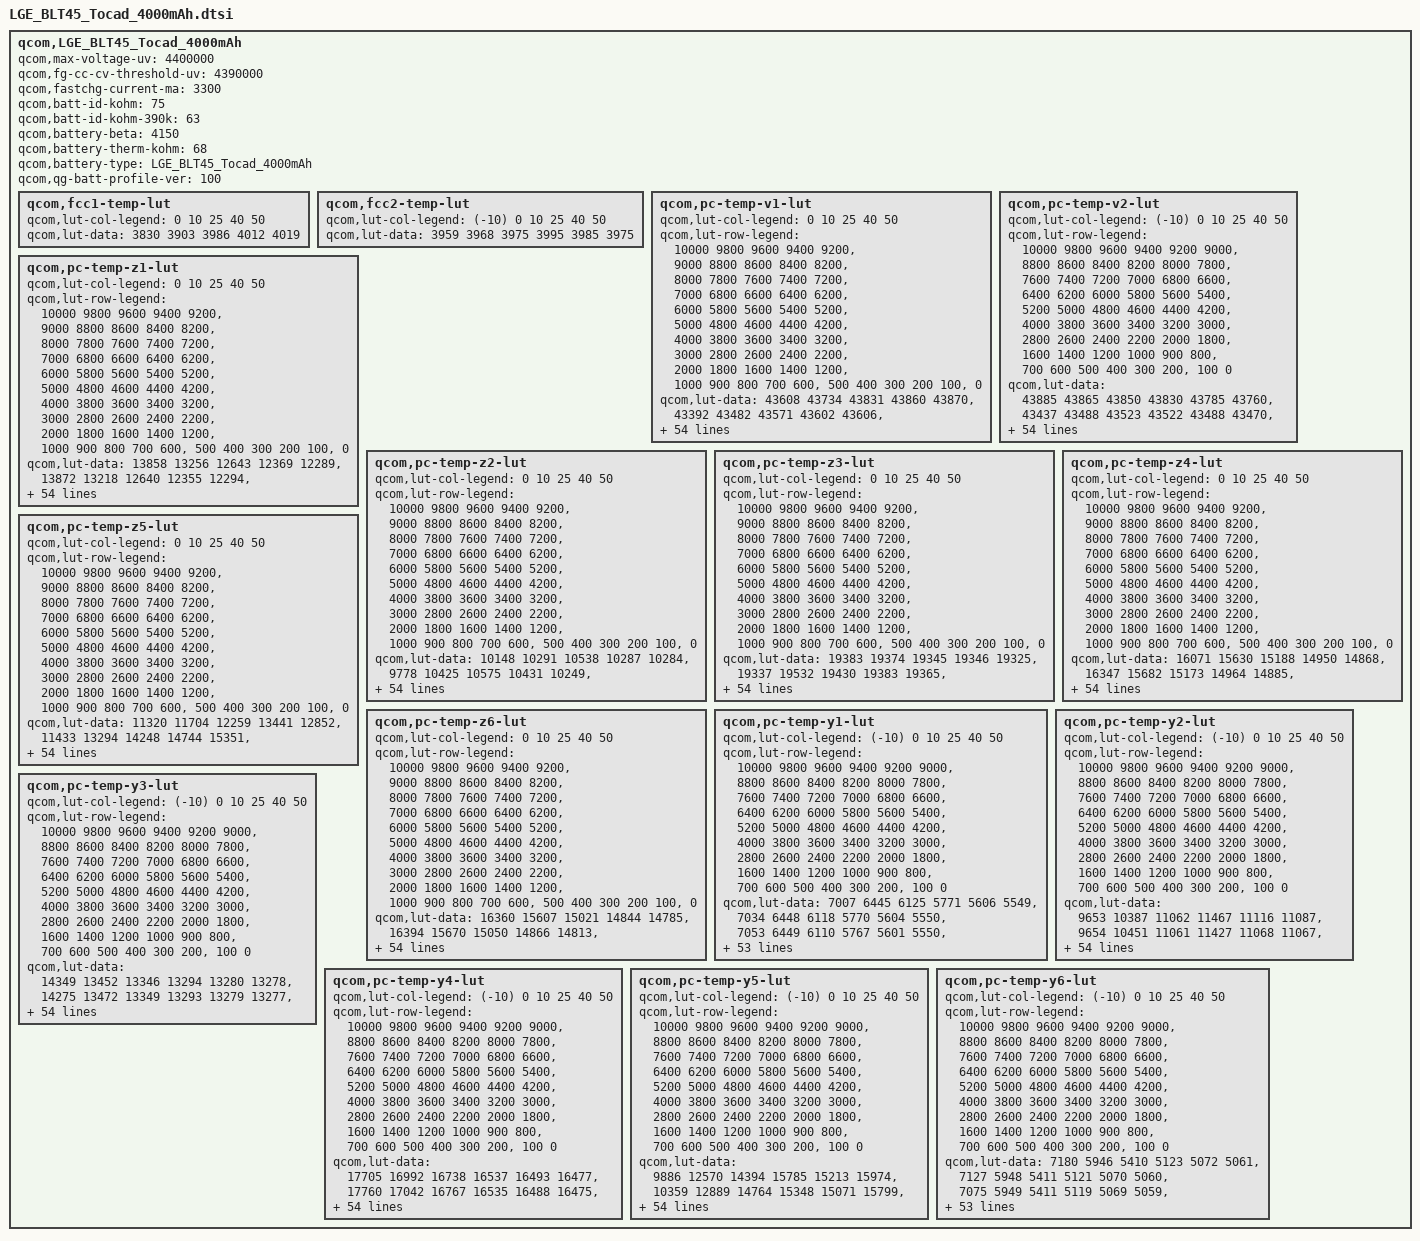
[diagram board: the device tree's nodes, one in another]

qcom,LGE_BLT45_Tocad_4000mAh {
    /* 3939240_LGE_BLT45_4000mAh_averaged_MasterSlave_Apr9th2019 */
    qcom,max-voltage-uv = <4400000>;
    qcom,fg-cc-cv-threshold-uv = <4390000>;
    qcom,fastchg-current-ma = <3300>;
    qcom,batt-id-kohm = <75>;
	qcom,batt-id-kohm-390k = <63>;
    qcom,battery-beta = <4150>;
    qcom,battery-therm-kohm = <68>;
    qcom,battery-type = "LGE_BLT45_Tocad_4000mAh";
    qcom,qg-batt-profile-ver = <100>;

	qcom,fcc1-temp-lut {
		qcom,lut-col-legend = <0 10 25 40 50>;
		qcom,lut-data = <3830 3903 3986 4012 4019>;
	};

	qcom,fcc2-temp-lut {
		qcom,lut-col-legend = <(-10) 0 10 25 40 50>;
		qcom,lut-data = <3959 3968 3975 3995 3985 3975>;
	};

	qcom,pc-temp-v1-lut {
		qcom,lut-col-legend = <0 10 25 40 50>;
		qcom,lut-row-legend = <10000 9800 9600 9400 9200>,
			<9000 8800 8600 8400 8200>,
			<8000 7800 7600 7400 7200>,
			<7000 6800 6600 6400 6200>,
			<6000 5800 5600 5400 5200>,
			<5000 4800 4600 4400 4200>,
			<4000 3800 3600 3400 3200>,
			<3000 2800 2600 2400 2200>,
			<2000 1800 1600 1400 1200>,
			<1000 900 800 700 600>,
			<500 400 300 200 100>,
			<0>;
		qcom,lut-data = <43608 43734 43831 43860 43870>,
			<43392 43482 43571 43602 43606>,
			<43120 43233 43317 43353 43362>,
			<42850 42988 43072 43110 43123>,
			<42611 42748 42835 42874 42890>,
			<42383 42512 42599 42641 42660>,
			<42159 42281 42365 42409 42430>,
			<41940 42055 42132 42179 42201>,
			<41727 41835 41904 41951 41974>,
			<41523 41619 41679 41722 41748>,
			<41325 41408 41458 41498 41524>,
			<41131 41202 41243 41280 41305>,
			<40940 41006 41031 41066 41089>,
			<40749 40821 40827 40859 40880>,
			<40538 40634 40626 40657 40675>,
			<40303 40425 40434 40462 40478>,
			<40095 40208 40249 40276 40292>,
			<39942 40028 40072 40099 40114>,
			<39813 39890 39909 39930 39942>,
			<39684 39756 39761 39774 39783>,
			<39556 39597 39594 39608 39617>,
			<39425 39421 39371 39395 39413>,
			<39283 39234 39137 39162 39188>,
			<39129 39011 38959 38981 39004>,
			<38979 38806 38811 38841 38855>,
			<38829 38694 38692 38719 38726>,
			<38690 38623 38601 38607 38610>,
			<38593 38562 38524 38505 38506>,
			<38520 38505 38446 38413 38412>,
			<38464 38454 38370 38327 38323>,
			<38425 38404 38301 38252 38244>,
			<38395 38356 38239 38184 38172>,
			<38365 38310 38184 38124 38105>,
			<38336 38270 38135 38070 38045>,
			<38307 38232 38093 38025 37992>,
			<38275 38194 38052 37979 37937>,
			<38242 38159 38012 37928 37876>,
			<38199 38117 37970 37870 37810>,
			<38131 38048 37907 37799 37732>,
			<38041 37948 37816 37709 37640>,
			<37947 37840 37713 37607 37537>,
			<37844 37722 37603 37497 37426>,
			<37713 37587 37477 37371 37301>,
			<37536 37421 37316 37214 37143>,
			<37367 37264 37167 37074 37006>,
			<37256 37167 37067 36980 36922>,
			<37215 37133 37044 36956 36894>,
			<37181 37108 37020 36936 36874>,
			<37147 37089 36999 36909 36847>,
			<37060 36999 36910 36804 36723>,
			<36773 36705 36605 36482 36388>,
			<36322 36256 36159 36035 35941>,
			<35747 35679 35583 35457 35362>,
			<34967 34895 34799 34671 34575>,
			<33730 33660 33573 33443 33346>,
			<30000 30000 30000 30000 30000>;
	};

	qcom,pc-temp-v2-lut {
		qcom,lut-col-legend = <(-10) 0 10 25 40 50>;
		qcom,lut-row-legend = <10000 9800 9600 9400 9200 9000>,
			<8800 8600 8400 8200 8000 7800>,
			<7600 7400 7200 7000 6800 6600>,
			<6400 6200 6000 5800 5600 5400>,
			<5200 5000 4800 4600 4400 4200>,
			<4000 3800 3600 3400 3200 3000>,
			<2800 2600 2400 2200 2000 1800>,
			<1600 1400 1200 1000 900 800>,
			<700 600 500 400 300 200>,
			<100 0>;
		qcom,lut-data = <43885 43865 43850 43830 43785 43760>,
			<43437 43488 43523 43522 43488 43470>,
			<43030 43147 43220 43235 43209 43197>,
			<42672 42851 42946 42972 42950 42941>,
			<42354 42594 42699 42731 42711 42702>,
			<42060 42347 42460 42497 42477 42469>,
			<41761 42096 42220 42262 42243 42236>,
			<41489 41849 41985 42030 42012 42006>,
			<41327 41595 41756 41803 41784 41779>,
			<41243 41322 41533 41579 41560 41555>,
			<41141 41095 41316 41358 41339 41335>,
			<40902 40961 41106 41142 41124 41119>,
			<40546 40853 40900 40928 40913 40907>,
			<40228 40676 40695 40722 40708 40703>,
			<39933 40358 40486 40521 40507 40505>,
			<39666 40045 40283 40326 40314 40314>,
			<39443 39841 40093 40138 40130 40129>,
			<39246 39670 39909 39957 39954 39951>,
			<39056 39478 39713 39779 39781 39777>,
			<38864 39257 39503 39608 39615 39613>,
			<38693 39042 39294 39427 39440 39440>,
			<38559 38852 39093 39209 39223 39225>,
			<38445 38679 38899 38982 38992 38994>,
			<38355 38521 38735 38804 38811 38812>,
			<38283 38369 38595 38660 38668 38670>,
			<38223 38245 38472 38535 38543 38548>,
			<38165 38164 38362 38424 38432 38436>,
			<38113 38102 38263 38325 38332 38335>,
			<38062 38048 38170 38235 38242 38243>,
			<38014 38003 38079 38154 38159 38157>,
			<37968 37962 37999 38079 38083 38079>,
			<37920 37919 37930 38008 38014 38010>,
			<37870 37877 37872 37941 37950 37946>,
			<37817 37833 37824 37876 37883 37877>,
			<37761 37786 37790 37814 37813 37800>,
			<37701 37737 37754 37748 37736 37713>,
			<37639 37682 37708 37675 37639 37606>,
			<37577 37622 37651 37598 37529 37483>,
			<37508 37554 37587 37522 37435 37379>,
			<37430 37474 37516 37450 37360 37298>,
			<37345 37384 37433 37372 37282 37220>,
			<37252 37283 37331 37276 37189 37126>,
			<37151 37168 37206 37166 37083 37020>,
			<37056 37042 37056 37033 36952 36890>,
			<36967 36909 36912 36915 36847 36786>,
			<36885 36788 36828 36857 36797 36743>,
			<36842 36743 36803 36839 36782 36728>,
			<36793 36692 36769 36815 36758 36707>,
			<36723 36631 36718 36768 36715 36659>,
			<36598 36520 36603 36646 36567 36499>,
			<36344 36281 36321 36303 36216 36126>,
			<35928 35845 35835 35806 35721 35626>,
			<35327 35242 35204 35163 35079 34980>,
			<34477 34399 34327 34291 34191 34104>,
			<33047 33059 33089 32944 32855 32565>,
			<29463 27828 27740 27731 27651 27624>;
	};

	qcom,pc-temp-z1-lut {
		qcom,lut-col-legend = <0 10 25 40 50>;
		qcom,lut-row-legend = <10000 9800 9600 9400 9200>,
			<9000 8800 8600 8400 8200>,
			<8000 7800 7600 7400 7200>,
			<7000 6800 6600 6400 6200>,
			<6000 5800 5600 5400 5200>,
			<5000 4800 4600 4400 4200>,
			<4000 3800 3600 3400 3200>,
			<3000 2800 2600 2400 2200>,
			<2000 1800 1600 1400 1200>,
			<1000 900 800 700 600>,
			<500 400 300 200 100>,
			<0>;
		qcom,lut-data = <13858 13256 12643 12369 12289>,
			<13872 13218 12640 12355 12294>,
			<13874 13206 12633 12351 12288>,
			<13873 13201 12622 12346 12283>,
			<13859 13200 12605 12340 12280>,
			<13839 13197 12591 12333 12276>,
			<13833 13194 12582 12328 12275>,
			<13836 13190 12575 12324 12274>,
			<13839 13174 12569 12322 12273>,
			<13838 13161 12563 12322 12272>,
			<13837 13155 12560 12321 12272>,
			<13834 13147 12560 12320 12272>,
			<13821 13140 12560 12319 12272>,
			<13802 13133 12559 12319 12273>,
			<13790 13128 12555 12319 12274>,
			<13779 13128 12553 12320 12275>,
			<13774 13128 12554 12321 12276>,
			<13779 13130 12556 12323 12278>,
			<13790 13136 12559 12325 12280>,
			<13796 13143 12563 12327 12282>,
			<13803 13144 12567 12330 12284>,
			<13809 13141 12571 12333 12286>,
			<13807 13140 12576 12335 12288>,
			<13801 13145 12580 12338 12291>,
			<13798 13152 12585 12342 12295>,
			<13804 13156 12589 12346 12299>,
			<13813 13159 12593 12351 12303>,
			<13815 13162 12598 12356 12306>,
			<13810 13163 12602 12361 12311>,
			<13807 13165 12607 12366 12315>,
			<13809 13167 12613 12370 12319>,
			<13815 13171 12620 12375 12323>,
			<13817 13174 12628 12380 12326>,
			<13817 13172 12632 12385 12330>,
			<13817 13166 12635 12390 12334>,
			<13817 13167 12638 12395 12337>,
			<13814 13179 12641 12399 12341>,
			<13815 13191 12646 12403 12346>,
			<13831 13197 12650 12407 12350>,
			<13854 13204 12657 12411 12354>,
			<13857 13206 12664 12416 12358>,
			<13845 13197 12672 12421 12363>,
			<13839 13194 12680 12425 12368>,
			<13832 13216 12688 12433 12372>,
			<13842 13204 12693 12441 12377>,
			<13811 13200 12697 12444 12379>,
			<13802 13197 12695 12446 12380>,
			<13805 13213 12699 12447 12382>,
			<13821 13196 12702 12450 12386>,
			<13823 13206 12711 12457 12392>,
			<13828 13226 12720 12467 12401>,
			<13828 13253 12733 12478 12411>,
			<13869 13260 12756 12495 12427>,
			<13907 13284 12779 12517 12448>,
			<13907 13284 12779 12517 12448>,
			<13907 13284 12779 12517 12448>;
	};

	qcom,pc-temp-z2-lut {
		qcom,lut-col-legend = <0 10 25 40 50>;
		qcom,lut-row-legend = <10000 9800 9600 9400 9200>,
			<9000 8800 8600 8400 8200>,
			<8000 7800 7600 7400 7200>,
			<7000 6800 6600 6400 6200>,
			<6000 5800 5600 5400 5200>,
			<5000 4800 4600 4400 4200>,
			<4000 3800 3600 3400 3200>,
			<3000 2800 2600 2400 2200>,
			<2000 1800 1600 1400 1200>,
			<1000 900 800 700 600>,
			<500 400 300 200 100>,
			<0>;
		qcom,lut-data = <10148 10291 10538 10287 10284>,
			<9778 10425 10575 10431 10249>,
			<10069 10437 10590 10479 10301>,
			<10258 10427 10580 10487 10327>,
			<10247 10413 10537 10477 10358>,
			<10223 10386 10498 10461 10383>,
			<10203 10352 10467 10437 10343>,
			<10188 10328 10445 10407 10258>,
			<10175 10308 10445 10400 10217>,
			<10167 10298 10457 10414 10183>,
			<10161 10302 10469 10426 10156>,
			<10159 10312 10480 10413 10160>,
			<10162 10324 10490 10379 10172>,
			<10166 10348 10497 10342 10183>,
			<10163 10370 10502 10293 10192>,
			<10145 10381 10506 10261 10201>,
			<10132 10388 10510 10264 10217>,
			<10151 10397 10514 10275 10239>,
			<10190 10408 10515 10287 10252>,
			<10212 10416 10520 10299 10260>,
			<10223 10419 10528 10319 10269>,
			<10229 10420 10573 10413 10292>,
			<10229 10420 10628 10562 10331>,
			<10227 10397 10615 10590 10365>,
			<10226 10368 10528 10502 10400>,
			<10231 10371 10479 10434 10422>,
			<10240 10399 10554 10498 10415>,
			<10249 10425 10655 10619 10393>,
			<10259 10443 10671 10636 10354>,
			<10269 10456 10668 10531 10240>,
			<10277 10461 10663 10447 10156>,
			<10285 10463 10618 10439 10155>,
			<10294 10464 10558 10435 10158>,
			<10307 10463 10550 10426 10165>,
			<10322 10460 10561 10408 10192>,
			<10336 10462 10576 10397 10229>,
			<10351 10474 10600 10436 10274>,
			<10365 10493 10633 10517 10328>,
			<10382 10513 10672 10572 10363>,
			<10396 10537 10725 10618 10391>,
			<10387 10553 10757 10641 10404>,
			<10320 10560 10764 10615 10400>,
			<10441 10570 10769 10569 10391>,
			<11594 10592 10774 10534 10370>,
			<12468 10731 10808 10517 10370>,
			<13819 10827 10803 10531 10382>,
			<13675 10825 10796 10528 10387>,
			<16242 11752 10781 10499 10387>,
			<16177 21159 10776 10567 10483>,
			<15624 11115 10955 10652 10471>,
			<14491 11226 11058 10469 10239>,
			<11416 11111 11051 10394 10189>,
			<11184 10970 10971 10340 10164>,
			<10509 10742 10949 10296 10104>,
			<10509 10742 10949 10296 10104>,
			<10509 10742 10949 10296 10104>;
	};

	qcom,pc-temp-z3-lut {
		qcom,lut-col-legend = <0 10 25 40 50>;
		qcom,lut-row-legend = <10000 9800 9600 9400 9200>,
			<9000 8800 8600 8400 8200>,
			<8000 7800 7600 7400 7200>,
			<7000 6800 6600 6400 6200>,
			<6000 5800 5600 5400 5200>,
			<5000 4800 4600 4400 4200>,
			<4000 3800 3600 3400 3200>,
			<3000 2800 2600 2400 2200>,
			<2000 1800 1600 1400 1200>,
			<1000 900 800 700 600>,
			<500 400 300 200 100>,
			<0>;
		qcom,lut-data = <19383 19374 19345 19346 19325>,
			<19337 19532 19430 19383 19365>,
			<19649 19606 19486 19406 19381>,
			<19866 19653 19503 19420 19393>,
			<19891 19674 19510 19432 19403>,
			<19904 19682 19514 19437 19410>,
			<19908 19687 19514 19435 19408>,
			<19906 19686 19514 19430 19403>,
			<19903 19682 19510 19426 19398>,
			<19897 19676 19498 19422 19393>,
			<19885 19668 19485 19417 19387>,
			<19872 19657 19475 19410 19384>,
			<19847 19644 19466 19401 19380>,
			<19823 19625 19461 19394 19378>,
			<19824 19611 19459 19390 19376>,
			<19847 19608 19455 19385 19374>,
			<19863 19606 19446 19379 19369>,
			<19836 19603 19435 19372 19362>,
			<19784 19592 19429 19368 19357>,
			<19767 19581 19424 19365 19354>,
			<19768 19586 19423 19363 19353>,
			<19770 19600 19438 19369 19354>,
			<19781 19609 19458 19380 19358>,
			<19812 19613 19456 19381 19360>,
			<19831 19615 19432 19360 19361>,
			<19837 19613 19418 19344 19362>,
			<19840 19603 19416 19366 19373>,
			<19840 19596 19415 19408 19395>,
			<19834 19593 19423 19420 19400>,
			<19826 19591 19455 19422 19396>,
			<19814 19592 19474 19422 19390>,
			<19797 19597 19474 19419 19386>,
			<19780 19601 19475 19412 19382>,
			<19764 19599 19473 19403 19376>,
			<19750 19596 19463 19392 19368>,
			<19737 19592 19453 19382 19362>,
			<19725 19585 19445 19378 19358>,
			<19717 19579 19437 19375 19355>,
			<19714 19574 19432 19373 19355>,
			<19711 19570 19428 19372 19356>,
			<19657 19565 19424 19372 19357>,
			<19367 19558 19420 19370 19355>,
			<19260 19547 19416 19368 19352>,
			<19258 19531 19411 19368 19359>,
			<19257 19499 19399 19361 19359>,
			<19257 19462 19396 19355 19342>,
			<19257 19459 19381 19342 19340>,
			<19257 19439 19382 19339 19336>,
			<19257 19302 19357 19335 19318>,
			<19257 19397 19344 19335 19338>,
			<19257 19346 19329 19350 19361>,
			<19258 19326 19325 19356 19360>,
			<19258 19324 19324 19359 19361>,
			<19260 19317 19320 19357 19365>,
			<19260 19317 19320 19357 19365>,
			<19260 19317 19320 19357 19365>;
	};

	qcom,pc-temp-z4-lut {
		qcom,lut-col-legend = <0 10 25 40 50>;
		qcom,lut-row-legend = <10000 9800 9600 9400 9200>,
			<9000 8800 8600 8400 8200>,
			<8000 7800 7600 7400 7200>,
			<7000 6800 6600 6400 6200>,
			<6000 5800 5600 5400 5200>,
			<5000 4800 4600 4400 4200>,
			<4000 3800 3600 3400 3200>,
			<3000 2800 2600 2400 2200>,
			<2000 1800 1600 1400 1200>,
			<1000 900 800 700 600>,
			<500 400 300 200 100>,
			<0>;
		qcom,lut-data = <16071 15630 15188 14950 14868>,
			<16347 15682 15173 14964 14885>,
			<16162 15641 15147 14946 14879>,
			<15953 15469 15106 14924 14869>,
			<15774 15311 15039 14893 14848>,
			<15599 15208 14978 14861 14823>,
			<15467 15123 14932 14833 14801>,
			<15365 15056 14893 14807 14781>,
			<15282 15000 14863 14790 14769>,
			<15217 14955 14839 14778 14763>,
			<15162 14918 14822 14769 14757>,
			<15117 14886 14812 14762 14751>,
			<15083 14862 14803 14756 14742>,
			<15053 14840 14792 14750 14733>,
			<15015 14828 14777 14741 14724>,
			<14966 14829 14765 14733 14715>,
			<14938 14831 14758 14725 14709>,
			<14937 14830 14751 14718 14703>,
			<14936 14807 14743 14711 14697>,
			<14933 14784 14732 14704 14690>,
			<14906 14785 14727 14700 14686>,
			<14878 14796 14768 14733 14719>,
			<14870 14815 14836 14807 14793>,
			<14866 14898 14888 14852 14821>,
			<14865 14988 14938 14882 14825>,
			<14897 14996 14959 14896 14827>,
			<14942 14978 14948 14866 14808>,
			<14950 14957 14925 14803 14765>,
			<14946 14934 14895 14769 14743>,
			<14939 14908 14847 14753 14734>,
			<14927 14884 14810 14741 14726>,
			<14909 14860 14791 14732 14717>,
			<14893 14839 14778 14726 14709>,
			<14879 14823 14770 14721 14704>,
			<14867 14809 14764 14718 14701>,
			<14855 14799 14762 14717 14699>,
			<14845 14789 14761 14720 14702>,
			<14835 14784 14762 14726 14711>,
			<14825 14788 14766 14734 14718>,
			<14817 14797 14783 14745 14726>,
			<14864 14800 14794 14751 14730>,
			<15150 14787 14780 14742 14724>,
			<15252 14775 14764 14732 14716>,
			<15223 14772 14762 14734 14715>,
			<15113 14746 14746 14727 14706>,
			<15078 14744 14721 14711 14699>,
			<15072 14733 14715 14707 14687>,
			<15063 14740 14693 14685 14668>,
			<15046 14874 14695 14665 14661>,
			<15039 14769 14717 14674 14653>,
			<15058 14846 14765 14692 14663>,
			<15072 14876 14774 14688 14667>,
			<15085 14884 14776 14687 14669>,
			<15102 14897 14782 14691 14666>,
			<15102 14897 14782 14691 14666>,
			<15102 14897 14782 14691 14666>;
	};

	qcom,pc-temp-z5-lut {
		qcom,lut-col-legend = <0 10 25 40 50>;
		qcom,lut-row-legend = <10000 9800 9600 9400 9200>,
			<9000 8800 8600 8400 8200>,
			<8000 7800 7600 7400 7200>,
			<7000 6800 6600 6400 6200>,
			<6000 5800 5600 5400 5200>,
			<5000 4800 4600 4400 4200>,
			<4000 3800 3600 3400 3200>,
			<3000 2800 2600 2400 2200>,
			<2000 1800 1600 1400 1200>,
			<1000 900 800 700 600>,
			<500 400 300 200 100>,
			<0>;
		qcom,lut-data = <11320 11704 12259 13441 12852>,
			<11433 13294 14248 14744 15351>,
			<12924 14413 15677 16091 16626>,
			<14146 15283 16327 17081 17590>,
			<14595 16019 16694 17852 18542>,
			<14909 16663 17065 18376 19200>,
			<15196 17233 17559 18634 19441>,
			<15488 17753 18039 18837 19629>,
			<15723 18222 18413 19089 19687>,
			<15929 18738 18757 19535 19573>,
			<16187 19524 18891 19840 19433>,
			<16293 20342 18826 19598 19476>,
			<16086 20625 18742 19076 19703>,
			<15811 20681 18989 18954 20056>,
			<16293 20743 19979 19239 20908>,
			<18887 20960 20510 19478 21578>,
			<20736 21384 20342 19436 21489>,
			<19790 21848 20123 19336 21221>,
			<17946 22298 20277 19381 21242>,
			<17406 22978 21252 20102 22420>,
			<18205 25790 22864 21207 23460>,
			<19698 31828 29037 23091 23280>,
			<22895 34487 36146 25399 22592>,
			<29160 34401 35168 25216 21412>,
			<33746 34204 26514 19519 18144>,
			<36178 33028 20365 15081 15680>,
			<37816 29007 18517 16003 16514>,
			<37891 25960 17446 18237 18529>,
			<36602 24800 17783 20097 19739>,
			<34793 24067 20151 21681 20328>,
			<32525 24170 22863 23179 20926>,
			<29677 25596 25541 24859 21944>,
			<27540 27341 28119 26347 23122>,
			<25921 28985 29790 26594 23816>,
			<24756 30618 31114 26174 24327>,
			<24196 31477 31660 25773 24586>,
			<23806 32104 31247 25607 24381>,
			<23661 32483 30343 25413 23864>,
			<24531 32396 28987 24845 23219>,
			<25851 32027 26313 22847 21869>,
			<24524 31453 24143 21153 20593>,
			<14794 29963 23190 20630 19757>,
			<11273 27948 22349 20215 19297>,
			<11316 25125 20995 19599 20234>,
			<11579 25234 21000 18731 20568>,
			<11556 21157 21982 18367 17323>,
			<11531 20872 19643 16920 17578>,
			<11492 19396 21146 17731 18557>,
			<11474 12462 17813 19417 17393>,
			<11532 15506 15964 17769 21518>,
			<11582 13222 13611 16447 20820>,
			<11458 12555 13193 16639 19215>,
			<11364 12374 13010 16431 18294>,
			<11258 12123 12683 15549 17814>,
			<11258 12123 12683 15549 17814>,
			<11258 12123 12683 15549 17814>;
	};

	qcom,pc-temp-z6-lut {
		qcom,lut-col-legend = <0 10 25 40 50>;
		qcom,lut-row-legend = <10000 9800 9600 9400 9200>,
			<9000 8800 8600 8400 8200>,
			<8000 7800 7600 7400 7200>,
			<7000 6800 6600 6400 6200>,
			<6000 5800 5600 5400 5200>,
			<5000 4800 4600 4400 4200>,
			<4000 3800 3600 3400 3200>,
			<3000 2800 2600 2400 2200>,
			<2000 1800 1600 1400 1200>,
			<1000 900 800 700 600>,
			<500 400 300 200 100>,
			<0>;
		qcom,lut-data = <16360 15607 15021 14844 14785>,
			<16394 15670 15050 14866 14813>,
			<16364 15655 15062 14870 14819>,
			<16319 15575 15055 14869 14820>,
			<16226 15495 15024 14861 14816>,
			<16093 15435 14994 14849 14808>,
			<15995 15381 14972 14836 14799>,
			<15922 15335 14952 14821 14788>,
			<15862 15297 14933 14810 14779>,
			<15810 15263 14915 14803 14773>,
			<15765 15235 14901 14796 14768>,
			<15723 15209 14890 14788 14762>,
			<15680 15186 14881 14781 14757>,
			<15642 15162 14873 14774 14751>,
			<15617 15147 14865 14768 14747>,
			<15600 15145 14857 14762 14742>,
			<15584 15144 14848 14755 14736>,
			<15565 15140 14841 14748 14730>,
			<15545 15126 14834 14743 14725>,
			<15533 15113 14828 14739 14721>,
			<15523 15115 14825 14736 14718>,
			<15517 15128 14853 14756 14733>,
			<15521 15146 14894 14796 14767>,
			<15536 15186 14912 14810 14781>,
			<15554 15225 14923 14813 14786>,
			<15576 15228 14927 14815 14788>,
			<15596 15218 14922 14813 14785>,
			<15599 15207 14913 14809 14780>,
			<15596 15197 14908 14804 14774>,
			<15591 15188 14904 14799 14769>,
			<15582 15180 14900 14794 14763>,
			<15565 15175 14895 14789 14757>,
			<15551 15169 14890 14783 14752>,
			<15538 15163 14884 14777 14747>,
			<15528 15156 14878 14770 14741>,
			<15520 15151 14874 14765 14738>,
			<15513 15148 14870 14765 14738>,
			<15510 15146 14867 14766 14740>,
			<15512 15149 14868 14768 14742>,
			<15514 15157 14875 14773 14747>,
			<15513 15160 14879 14776 14750>,
			<15501 15155 14873 14772 14747>,
			<15495 15150 14866 14768 14743>,
			<15493 15147 14864 14770 14747>,
			<15460 15130 14856 14764 14744>,
			<15448 15118 14845 14755 14732>,
			<15449 15113 14836 14747 14727>,
			<15448 15108 14827 14736 14716>,
			<15446 15100 14816 14726 14704>,
			<15449 15111 14823 14731 14712>,
			<15467 15124 14838 14749 14731>,
			<15484 15134 14844 14754 14735>,
			<15509 15148 14850 14758 14740>,
			<15540 15165 14859 14764 14745>,
			<15540 15165 14859 14764 14745>,
			<15540 15165 14859 14764 14745>;
	};

	qcom,pc-temp-y1-lut {
		qcom,lut-col-legend = <(-10) 0 10 25 40 50>;
		qcom,lut-row-legend = <10000 9800 9600 9400 9200 9000>,
			<8800 8600 8400 8200 8000 7800>,
			<7600 7400 7200 7000 6800 6600>,
			<6400 6200 6000 5800 5600 5400>,
			<5200 5000 4800 4600 4400 4200>,
			<4000 3800 3600 3400 3200 3000>,
			<2800 2600 2400 2200 2000 1800>,
			<1600 1400 1200 1000 900 800>,
			<700 600 500 400 300 200>,
			<100 0>;
		qcom,lut-data = <7007 6445 6125 5771 5606 5549>,
			<7034 6448 6118 5770 5604 5550>,
			<7053 6449 6110 5767 5601 5550>,
			<7065 6451 6104 5764 5599 5549>,
			<7071 6451 6098 5761 5596 5548>,
			<7073 6450 6095 5758 5593 5547>,
			<7066 6447 6095 5755 5590 5546>,
			<7054 6442 6095 5751 5587 5544>,
			<7050 6441 6095 5748 5585 5543>,
			<7041 6442 6094 5746 5585 5542>,
			<7035 6442 6093 5743 5584 5541>,
			<7038 6442 6091 5741 5582 5541>,
			<7044 6443 6087 5739 5580 5542>,
			<7048 6444 6087 5738 5579 5542>,
			<7052 6451 6094 5737 5579 5543>,
			<7054 6456 6100 5736 5579 5543>,
			<7049 6457 6098 5738 5579 5543>,
			<7038 6458 6093 5741 5581 5544>,
			<7035 6458 6092 5742 5581 5545>,
			<7043 6458 6093 5741 5582 5546>,
			<7049 6459 6094 5740 5583 5548>,
			<7050 6460 6092 5741 5584 5549>,
			<7050 6462 6089 5744 5586 5550>,
			<7050 6462 6089 5746 5588 5551>,
			<7044 6458 6090 5749 5590 5552>,
			<7042 6455 6091 5752 5593 5554>,
			<7051 6459 6095 5756 5595 5557>,
			<7064 6469 6102 5761 5597 5559>,
			<7069 6473 6105 5764 5599 5562>,
			<7072 6470 6103 5770 5601 5565>,
			<7072 6468 6102 5773 5605 5567>,
			<7064 6466 6103 5775 5608 5569>,
			<7053 6462 6106 5777 5612 5571>,
			<7047 6462 6107 5780 5616 5573>,
			<7040 6467 6108 5785 5620 5576>,
			<7034 6472 6110 5789 5624 5580>,
			<7036 6471 6111 5793 5627 5583>,
			<7041 6466 6114 5796 5629 5586>,
			<7044 6464 6117 5801 5632 5589>,
			<7043 6464 6120 5809 5635 5592>,
			<7042 6464 6124 5815 5639 5594>,
			<7043 6465 6126 5816 5642 5596>,
			<7046 6467 6128 5816 5645 5599>,
			<7042 6470 6132 5820 5649 5601>,
			<7032 6472 6136 5829 5655 5605>,
			<7035 6474 6140 5832 5658 5609>,
			<7033 6479 6136 5837 5661 5609>,
			<7035 6497 6142 5836 5661 5609>,
			<7025 6498 6160 5845 5661 5610>,
			<7030 6486 6157 5847 5662 5612>,
			<7042 6494 6147 5850 5669 5617>,
			<7057 6510 6166 5861 5677 5625>,
			<7080 6551 6188 5882 5690 5636>,
			<7137 6574 6197 5908 5707 5650>,
			<7137 6574 6197 5908 5707 5650>,
			<7137 6574 6197 5908 5707 5650>;
	};

	qcom,pc-temp-y2-lut {
		qcom,lut-col-legend = <(-10) 0 10 25 40 50>;
		qcom,lut-row-legend = <10000 9800 9600 9400 9200 9000>,
			<8800 8600 8400 8200 8000 7800>,
			<7600 7400 7200 7000 6800 6600>,
			<6400 6200 6000 5800 5600 5400>,
			<5200 5000 4800 4600 4400 4200>,
			<4000 3800 3600 3400 3200 3000>,
			<2800 2600 2400 2200 2000 1800>,
			<1600 1400 1200 1000 900 800>,
			<700 600 500 400 300 200>,
			<100 0>;
		qcom,lut-data = <9653 10387 11062 11467 11116 11087>,
			<9654 10451 11061 11427 11068 11067>,
			<9655 10518 11056 11364 11034 11033>,
			<9657 10579 11047 11296 11012 10993>,
			<9658 10623 11037 11241 10997 10959>,
			<9658 10641 11024 11216 10988 10937>,
			<9659 10629 11005 11216 10988 10926>,
			<9659 10608 10985 11219 10996 10914>,
			<9659 10615 10980 11214 10997 10905>,
			<9660 10688 10982 11198 10989 10894>,
			<9660 10753 10983 11183 10977 10884>,
			<9661 10770 10979 11173 10959 10877>,
			<9661 10780 10972 11162 10938 10867>,
			<9661 10791 10980 11162 10931 10859>,
			<9660 10823 11044 11169 10928 10850>,
			<9659 10854 11107 11180 10926 10843>,
			<9659 10872 11136 11216 10965 10839>,
			<9659 10887 11155 11273 11046 10833>,
			<9659 10897 11154 11314 11114 10840>,
			<9659 10903 11114 11350 11191 10886>,
			<9659 10909 11082 11367 11235 10924>,
			<9658 10929 11103 11346 11198 10944>,
			<9658 10957 11152 11313 11131 10982>,
			<9658 10918 11193 11310 11116 11013>,
			<9657 10400 11232 11333 11125 11044>,
			<9657 9905 11263 11359 11138 11065>,
			<9656 9841 11281 11381 11162 11062>,
			<9656 9816 11293 11406 11196 11050>,
			<9655 9787 11314 11432 11224 11051>,
			<9655 9751 11356 11463 11253 11077>,
			<9655 9720 11386 11489 11274 11108>,
			<9654 9702 11259 11509 11274 11132>,
			<9654 9690 10968 11527 11264 11157>,
			<9654 9681 10879 11522 11261 11164>,
			<9654 9675 11062 11471 11267 11152>,
			<9654 9670 11227 11431 11272 11140>,
			<9653 9666 11201 11433 11269 11145>,
			<9653 9662 11144 11446 11266 11160>,
			<9653 9660 11078 11450 11269 11163>,
			<9653 9658 10998 11448 11288 11118>,
			<9653 9657 10911 11442 11304 11073>,
			<9653 9655 10834 11412 11286 11075>,
			<9653 9655 10744 11367 11251 11087>,
			<9653 9654 10407 11322 11247 11098>,
			<9653 9653 9990 11226 11214 11092>,
			<9653 9653 9875 11205 11153 10959>,
			<9653 9653 9889 11186 11089 10917>,
			<9653 9653 9827 11190 11046 10888>,
			<9653 9653 9806 11125 11052 10854>,
			<9652 9652 9770 11100 11043 10862>,
			<9652 9652 9714 11027 10980 10857>,
			<9652 9652 9687 10956 10923 10795>,
			<9652 9652 9673 10886 10848 10708>,
			<9652 9651 9666 10691 10730 10596>,
			<9652 9651 9666 10691 10730 10596>,
			<9652 9651 9666 10691 10730 10596>;
	};

	qcom,pc-temp-y3-lut {
		qcom,lut-col-legend = <(-10) 0 10 25 40 50>;
		qcom,lut-row-legend = <10000 9800 9600 9400 9200 9000>,
			<8800 8600 8400 8200 8000 7800>,
			<7600 7400 7200 7000 6800 6600>,
			<6400 6200 6000 5800 5600 5400>,
			<5200 5000 4800 4600 4400 4200>,
			<4000 3800 3600 3400 3200 3000>,
			<2800 2600 2400 2200 2000 1800>,
			<1600 1400 1200 1000 900 800>,
			<700 600 500 400 300 200>,
			<100 0>;
		qcom,lut-data = <14349 13452 13346 13294 13280 13278>,
			<14275 13472 13349 13293 13279 13277>,
			<14201 13487 13354 13293 13279 13277>,
			<14129 13495 13359 13292 13279 13277>,
			<14058 13500 13364 13292 13279 13277>,
			<13989 13501 13366 13292 13279 13278>,
			<13914 13497 13367 13292 13279 13278>,
			<13844 13490 13367 13292 13280 13279>,
			<13805 13485 13368 13293 13280 13280>,
			<13779 13483 13369 13295 13280 13280>,
			<13766 13480 13370 13298 13280 13280>,
			<13776 13468 13371 13299 13282 13280>,
			<13793 13451 13370 13301 13285 13280>,
			<13788 13443 13370 13302 13286 13281>,
			<13693 13441 13367 13303 13286 13284>,
			<13603 13439 13364 13305 13286 13286>,
			<13580 13432 13362 13307 13287 13286>,
			<13566 13422 13360 13310 13291 13285>,
			<13562 13411 13356 13310 13293 13285>,
			<13563 13401 13348 13310 13295 13288>,
			<13564 13391 13341 13309 13297 13289>,
			<13569 13384 13336 13305 13293 13286>,
			<13582 13378 13331 13298 13286 13279>,
			<13598 13364 13328 13295 13282 13277>,
			<13626 13311 13325 13292 13280 13277>,
			<13662 13267 13323 13291 13279 13277>,
			<13699 13266 13323 13291 13278 13277>,
			<13741 13267 13322 13290 13278 13277>,
			<13787 13270 13321 13291 13278 13277>,
			<13837 13277 13317 13292 13279 13276>,
			<13893 13287 13312 13293 13280 13276>,
			<13957 13299 13307 13293 13280 13276>,
			<14029 13316 13300 13293 13280 13277>,
			<14101 13337 13299 13293 13280 13278>,
			<14172 13361 13311 13293 13280 13278>,
			<14244 13391 13323 13292 13280 13279>,
			<14322 13430 13324 13290 13279 13278>,
			<14406 13481 13324 13288 13278 13276>,
			<14486 13541 13324 13287 13277 13275>,
			<14557 13613 13328 13288 13276 13276>,
			<14626 13697 13333 13288 13276 13277>,
			<14695 13792 13337 13287 13276 13277>,
			<14763 13903 13340 13285 13276 13277>,
			<14831 14033 13334 13289 13277 13276>,
			<14901 14177 13329 13291 13277 13276>,
			<14980 14278 13342 13292 13279 13279>,
			<14918 14259 13347 13296 13285 13284>,
			<15004 14335 13360 13301 13289 13288>,
			<15090 14421 13376 13307 13294 13290>,
			<15193 14502 13399 13315 13293 13288>,
			<15303 14599 13413 13309 13285 13284>,
			<15446 14709 13426 13310 13291 13286>,
			<15616 14885 13475 13319 13295 13290>,
			<15860 15107 13544 13332 13299 13296>,
			<15860 15107 13544 13332 13299 13296>,
			<15860 15107 13544 13332 13299 13296>;
	};

	qcom,pc-temp-y4-lut {
		qcom,lut-col-legend = <(-10) 0 10 25 40 50>;
		qcom,lut-row-legend = <10000 9800 9600 9400 9200 9000>,
			<8800 8600 8400 8200 8000 7800>,
			<7600 7400 7200 7000 6800 6600>,
			<6400 6200 6000 5800 5600 5400>,
			<5200 5000 4800 4600 4400 4200>,
			<4000 3800 3600 3400 3200 3000>,
			<2800 2600 2400 2200 2000 1800>,
			<1600 1400 1200 1000 900 800>,
			<700 600 500 400 300 200>,
			<100 0>;
		qcom,lut-data = <17705 16992 16738 16537 16493 16477>,
			<17760 17042 16767 16535 16488 16475>,
			<17817 17135 16796 16534 16485 16473>,
			<17871 17241 16822 16534 16483 16471>,
			<17916 17329 16841 16535 16483 16470>,
			<17950 17368 16848 16537 16483 16470>,
			<17969 17366 16843 16540 16485 16470>,
			<17984 17361 16834 16545 16488 16471>,
			<18045 17350 16832 16550 16492 16472>,
			<18289 17315 16833 16554 16497 16475>,
			<18468 17291 16834 16559 16502 16480>,
			<18278 17441 16839 16565 16506 16484>,
			<17869 17714 16850 16575 16510 16490>,
			<17641 17746 16868 16585 16516 16494>,
			<17528 17451 16908 16599 16525 16498>,
			<17443 17216 16941 16614 16535 16503>,
			<17377 17213 16952 16632 16543 16512>,
			<17322 17216 16960 16652 16553 16523>,
			<17252 17205 16955 16674 16567 16537>,
			<17148 17099 16903 16701 16592 16555>,
			<17061 16970 16832 16716 16608 16566>,
			<17025 16874 16757 16664 16578 16547>,
			<17001 16790 16678 16574 16522 16505>,
			<16992 16770 16637 16536 16498 16485>,
			<16988 16791 16616 16517 16487 16478>,
			<16986 16811 16603 16510 16483 16474>,
			<16989 16813 16597 16511 16484 16475>,
			<16999 16813 16593 16515 16487 16476>,
			<17008 16814 16589 16521 16491 16478>,
			<17015 16816 16583 16530 16498 16485>,
			<17021 16819 16579 16541 16508 16494>,
			<17028 16824 16584 16552 16521 16505>,
			<17036 16831 16597 16563 16534 16518>,
			<17046 16840 16601 16564 16538 16522>,
			<17060 16852 16597 16562 16536 16519>,
			<17074 16864 16595 16557 16534 16514>,
			<17082 16873 16603 16539 16518 16503>,
			<17089 16881 16617 16515 16490 16484>,
			<17091 16884 16631 16510 16483 16478>,
			<17088 16882 16645 16513 16486 16479>,
			<17082 16881 16656 16517 16489 16479>,
			<17075 16882 16663 16525 16490 16479>,
			<17065 16884 16667 16532 16490 16478>,
			<17070 16889 16685 16530 16483 16469>,
			<17095 16903 16712 16530 16478 16462>,
			<17116 16939 16730 16539 16489 16475>,
			<17094 16943 16743 16555 16498 16489>,
			<17123 17011 16784 16570 16516 16520>,
			<17170 17102 16834 16596 16550 16547>,
			<17197 17164 16868 16609 16522 16522>,
			<17183 17172 16864 16568 16494 16475>,
			<17142 17142 16856 16578 16492 16476>,
			<17141 17146 16891 16609 16502 16487>,
			<17170 17180 16952 16698 16550 16532>,
			<17170 17180 16952 16698 16550 16532>,
			<17170 17180 16952 16698 16550 16532>;
	};

	qcom,pc-temp-y5-lut {
		qcom,lut-col-legend = <(-10) 0 10 25 40 50>;
		qcom,lut-row-legend = <10000 9800 9600 9400 9200 9000>,
			<8800 8600 8400 8200 8000 7800>,
			<7600 7400 7200 7000 6800 6600>,
			<6400 6200 6000 5800 5600 5400>,
			<5200 5000 4800 4600 4400 4200>,
			<4000 3800 3600 3400 3200 3000>,
			<2800 2600 2400 2200 2000 1800>,
			<1600 1400 1200 1000 900 800>,
			<700 600 500 400 300 200>,
			<100 0>;
		qcom,lut-data = <9886 12570 14394 15785 15213 15974>,
			<10359 12889 14764 15348 15071 15799>,
			<10789 13412 15093 14910 14844 15594>,
			<11141 13983 15358 14490 14577 15388>,
			<11381 14447 15536 14106 14312 15213>,
			<11476 14648 15604 13776 14096 15096>,
			<11380 14633 15548 13464 13808 15015>,
			<11213 14584 15427 13198 13455 14910>,
			<11296 14382 15318 13118 13242 14750>,
			<12269 13473 15193 13295 13026 14461>,
			<13478 12816 15014 13432 12909 14168>,
			<14667 13421 14554 13425 13153 13855>,
			<15824 14604 13971 13414 13558 13544>,
			<15845 15099 13870 13397 13597 13549>,
			<13648 15240 14126 13321 13287 14041>,
			<11808 15373 14479 13282 13067 14416>,
			<11770 15615 14872 13435 13256 14163>,
			<11794 15906 15327 13752 13695 13679>,
			<11787 16123 15715 14145 14152 13630>,
			<11614 16305 16116 14901 14705 14235>,
			<11379 16410 16402 15680 15220 14720>,
			<11163 16423 16555 16399 15667 14717>,
			<10945 16430 16697 16998 16032 14693>,
			<10880 16176 16709 17043 16056 14742>,
			<10892 13410 16508 16675 15675 15233>,
			<10905 10891 16333 16304 15218 15646>,
			<10890 10783 16437 16034 14810 15530>,
			<10848 10780 16675 15804 14440 15200>,
			<10833 10790 16678 15829 14385 14862>,
			<10893 10907 15956 16240 14588 14377>,
			<10981 11060 15103 16625 14785 14039>,
			<11053 11165 14340 16784 14854 14122>,
			<11124 11258 13388 16904 14923 14407>,
			<11148 11333 13233 17079 15103 14788>,
			<11098 11389 14846 17440 15719 15587>,
			<11039 11443 16345 17660 16176 16214>,
			<11055 11521 16100 17279 16021 16099>,
			<11136 11616 15339 16519 15612 15710>,
			<11193 11659 15072 16003 15205 15430>,
			<11217 11669 15169 15667 14688 15260>,
			<11231 11674 15263 15275 14253 15133>,
			<11189 11592 15219 14469 13995 15030>,
			<11027 11383 15013 13853 13827 14951>,
			<10893 11382 13621 14538 14396 15184>,
			<10775 11419 12109 14616 14620 15312>,
			<10910 11381 12080 14208 13775 14593>,
			<10985 11508 12192 14157 15111 15484>,
			<11096 11508 12259 14510 15338 15980>,
			<11138 11551 12388 14741 15764 15505>,
			<11217 11605 12491 15751 15773 15294>,
			<11076 11738 12298 15714 14258 15382>,
			<11016 11579 11862 15083 16705 15603>,
			<10835 11377 11859 15749 17275 17014>,
			<10848 11259 11863 16837 17592 18941>,
			<10848 11259 11863 16837 17592 18941>,
			<10848 11259 11863 16837 17592 18941>;
	};

	qcom,pc-temp-y6-lut {
		qcom,lut-col-legend = <(-10) 0 10 25 40 50>;
		qcom,lut-row-legend = <10000 9800 9600 9400 9200 9000>,
			<8800 8600 8400 8200 8000 7800>,
			<7600 7400 7200 7000 6800 6600>,
			<6400 6200 6000 5800 5600 5400>,
			<5200 5000 4800 4600 4400 4200>,
			<4000 3800 3600 3400 3200 3000>,
			<2800 2600 2400 2200 2000 1800>,
			<1600 1400 1200 1000 900 800>,
			<700 600 500 400 300 200>,
			<100 0>;
		qcom,lut-data = <7180 5946 5410 5123 5072 5061>,
			<7127 5948 5411 5121 5070 5060>,
			<7075 5949 5411 5119 5069 5059>,
			<7022 5949 5411 5118 5069 5059>,
			<6970 5949 5411 5117 5068 5059>,
			<6919 5949 5411 5117 5068 5059>,
			<6856 5938 5404 5117 5068 5059>,
			<6799 5915 5393 5118 5069 5060>,
			<6793 5891 5386 5119 5070 5061>,
			<6830 5863 5382 5121 5072 5062>,
			<6859 5847 5380 5124 5074 5063>,
			<6814 5877 5377 5126 5076 5065>,
			<6707 5932 5376 5130 5079 5066>,
			<6619 5936 5376 5133 5081 5068>,
			<6540 5856 5382 5138 5084 5071>,
			<6479 5787 5387 5143 5086 5074>,
			<6446 5778 5388 5149 5090 5077>,
			<6423 5773 5388 5157 5095 5080>,
			<6401 5762 5384 5164 5101 5083>,
			<6374 5727 5363 5171 5110 5090>,
			<6358 5689 5336 5174 5115 5095>,
			<6359 5665 5311 5157 5104 5087>,
			<6366 5646 5286 5126 5083 5070>,
			<6377 5630 5274 5113 5073 5063>,
			<6401 5616 5267 5106 5068 5060>,
			<6433 5608 5264 5104 5066 5059>,
			<6466 5614 5265 5104 5067 5060>,
			<6505 5633 5267 5106 5067 5060>,
			<6545 5656 5267 5108 5069 5061>,
			<6588 5684 5267 5113 5072 5063>,
			<6633 5716 5266 5117 5076 5065>,
			<6684 5751 5267 5122 5080 5069>,
			<6739 5790 5269 5125 5085 5074>,
			<6795 5833 5273 5126 5086 5075>,
			<6852 5882 5286 5126 5085 5075>,
			<6910 5936 5302 5125 5085 5074>,
			<6971 5996 5316 5121 5081 5071>,
			<7033 6062 5329 5113 5072 5065>,
			<7093 6133 5346 5112 5069 5062>,
			<7146 6208 5368 5114 5070 5063>,
			<7196 6289 5394 5116 5072 5064>,
			<7246 6377 5422 5119 5072 5065>,
			<7294 6473 5452 5122 5073 5065>,
			<7347 6578 5484 5126 5071 5062>,
			<7407 6693 5522 5130 5071 5060>,
			<7471 6780 5561 5136 5076 5067>,
			<7422 6769 5572 5144 5083 5074>,
			<7493 6850 5612 5153 5091 5087>,
			<7575 6940 5660 5166 5105 5096>,
			<7662 7021 5705 5176 5096 5087>,
			<7746 7100 5736 5162 5083 5072>,
			<7850 7181 5779 5171 5088 5074>,
			<7990 7325 5880 5192 5096 5081>,
			<8205 7509 6000 5233 5114 5101>,
			<8205 7509 6000 5233 5114 5101>,
			<8205 7509 6000 5233 5114 5101>;
	};

};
